# BL808 register map
Vendor: Bouffalo Lab; File version: 0.1
Registers are 32-bit, read-write, reset 0x0 unless marked. A register's access mark holds for its fields unless they carry their own. Offsets are from the block's base; [hi:lo] are bit positions; {n}, {i} and the like mark numbered series.

## FLASH — Quad Serial Flash control
Base 0x2000B000
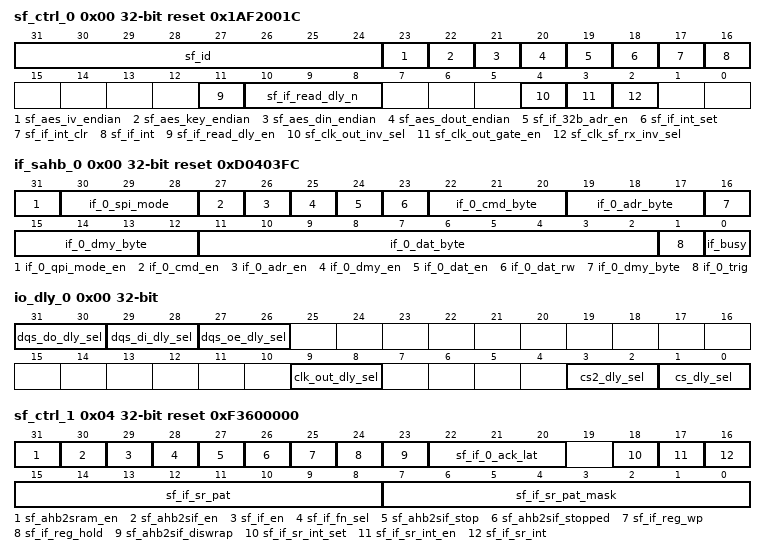
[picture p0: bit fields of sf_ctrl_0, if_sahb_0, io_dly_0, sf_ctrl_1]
0x00 sf_ctrl_0 reset 0x1AF2001C
  [31:24] sf_id, [23] sf_aes_iv_endian, [22] sf_aes_key_endian, [21] sf_aes_din_endian, [20] sf_aes_dout_endian, [19] sf_if_32b_adr_en, [18] sf_if_int_set, [17] sf_if_int_clr, [16] sf_if_int ro, [11] sf_if_read_dly_en, [10:8] sf_if_read_dly_n, [4] sf_clk_out_inv_sel, [3] sf_clk_out_gate_en, [2] sf_clk_sf_rx_inv_sel
0x00 if_sahb_0 reset 0xD0403FC — sf_if_sahb_0
  [31] if_0_qpi_mode_en, [30:28] if_0_spi_mode, [27] if_0_cmd_en, [26] if_0_adr_en, [25] if_0_dmy_en, [24] if_0_dat_en, [23] if_0_dat_rw, [22:20] if_0_cmd_byte, [19:17] if_0_adr_byte, [16:12] if_0_dmy_byte, [11:2] if_0_dat_byte, [1] if_0_trig, [0] if_busy ro
0x00 io_dly_0 — if_io_dly_0
  [31:30] dqs_do_dly_sel, [29:28] dqs_di_dly_sel, [27:26] dqs_oe_dly_sel, [9:8] clk_out_dly_sel, [3:2] cs2_dly_sel, [1:0] cs_dly_sel
{0x0+4i} sf_aes_key_{i} (i=0..7)
0x04 sf_ctrl_1 reset 0xF3600000
  [31] sf_ahb2sram_en, [30] sf_ahb2sif_en, [29] sf_if_en, [28] sf_if_fn_sel, [27] sf_ahb2sif_stop, [26] sf_ahb2sif_stopped ro, [25] sf_if_reg_wp, [24] sf_if_reg_hold, [23] sf_ahb2sif_diswrap, [22:20] sf_if_0_ack_lat, [18] sf_if_sr_int_set, [17] sf_if_sr_int_en, [16] sf_if_sr_int ro, [15:8] sf_if_sr_pat, [7:0] sf_if_sr_pat_mask
0x04 if_sahb_1 reset 0x3000000 — sf_if_sahb_1
  [31:0] if_0_cmd_buf_0
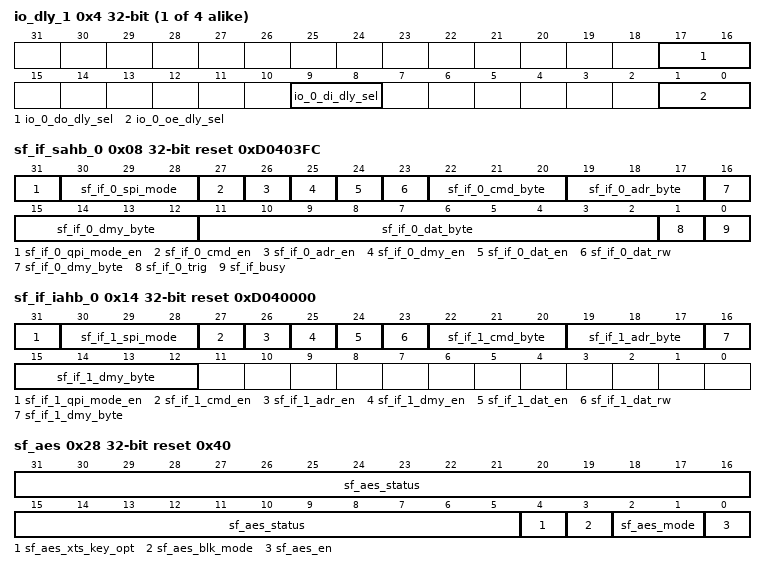
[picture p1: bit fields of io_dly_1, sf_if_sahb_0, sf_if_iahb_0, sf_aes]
{0x0+4i} io_dly_{i} (i=1..4) — if_io_dly_{i}
  [17:16] io_{i-1}_do_dly_sel, [9:8] io_{i-1}_di_dly_sel, [1:0] io_{i-1}_oe_dly_sel
0x08 sf_if_sahb_0 reset 0xD0403FC
  [31] sf_if_0_qpi_mode_en, [30:28] sf_if_0_spi_mode, [27] sf_if_0_cmd_en, [26] sf_if_0_adr_en, [25] sf_if_0_dmy_en, [24] sf_if_0_dat_en, [23] sf_if_0_dat_rw, [22:20] sf_if_0_cmd_byte, [19:17] sf_if_0_adr_byte, [16:12] sf_if_0_dmy_byte, [11:2] sf_if_0_dat_byte, [1] sf_if_0_trig, [0] sf_if_busy ro
0x08 if_sahb_2 — sf_if_sahb_2
  [31:0] if_0_cmd_buf_1
0x0C sf_if_sahb_1 reset 0x3000000
  [31:0] sf_if_0_cmd_buf_0
0x10 sf_if_sahb_2
  [31:0] sf_if_0_cmd_buf_1
0x14 sf_if_iahb_0 reset 0xD040000
  [31] sf_if_1_qpi_mode_en, [30:28] sf_if_1_spi_mode, [27] sf_if_1_cmd_en, [26] sf_if_1_adr_en, [25] sf_if_1_dmy_en, [24] sf_if_1_dat_en, [23] sf_if_1_dat_rw, [22:20] sf_if_1_cmd_byte, [19:17] sf_if_1_adr_byte, [16:12] sf_if_1_dmy_byte
0x18 sf_if_iahb_1 reset 0x3000000
  [31:0] sf_if_1_cmd_buf_0
0x1C sf_if_iahb_2
  [31:0] sf_if_1_cmd_buf_1
0x20 sf_if_status_0
  [31:0] sf_if_status_0 ro
{0x20+4i} sf_aes_iv_w{i} (i=0..3)
0x24 sf_if_status_1 reset 0x20000000
  [31:0] sf_if_status_1 ro
0x28 sf_aes reset 0x40
  [31:5] sf_aes_status ro, [4] sf_aes_xts_key_opt, [3] sf_aes_blk_mode, [2:1] sf_aes_mode, [0] sf_aes_en
0x2C sf_ahb2sif_status reset 0x1010003
  [31:0] sf_ahb2sif_status ro
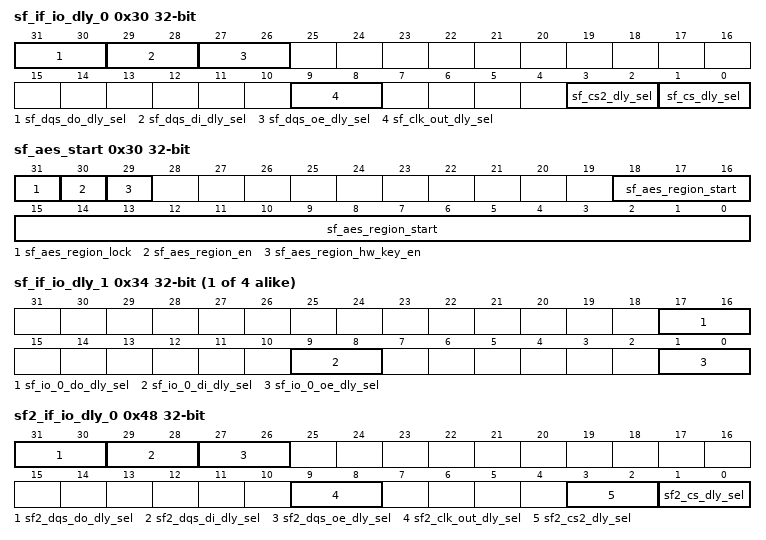
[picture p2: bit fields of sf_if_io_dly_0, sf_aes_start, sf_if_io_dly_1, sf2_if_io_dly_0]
0x30 sf_if_io_dly_0
  [31:30] sf_dqs_do_dly_sel, [29:28] sf_dqs_di_dly_sel, [27:26] sf_dqs_oe_dly_sel, [9:8] sf_clk_out_dly_sel, [3:2] sf_cs2_dly_sel, [1:0] sf_cs_dly_sel
0x30 sf_aes_start
  [31] sf_aes_region_lock, [30] sf_aes_region_en, [29] sf_aes_region_hw_key_en, [18:0] sf_aes_region_start
{0x30+4i} sf_if_io_dly_{i} (i=1..4)
  [17:16] sf_io_{i-1}_do_dly_sel, [9:8] sf_io_{i-1}_di_dly_sel, [1:0] sf_io_{i-1}_oe_dly_sel
0x34 sf_aes_end reset 0x3FFF
  [18:0] sf_aes_region_end
0x44 sf_reserved reset 0xFFFF
0x48 sf2_if_io_dly_0
  [31:30] sf2_dqs_do_dly_sel, [29:28] sf2_dqs_di_dly_sel, [27:26] sf2_dqs_oe_dly_sel, [9:8] sf2_clk_out_dly_sel, [3:2] sf2_cs2_dly_sel, [1:0] sf2_cs_dly_sel
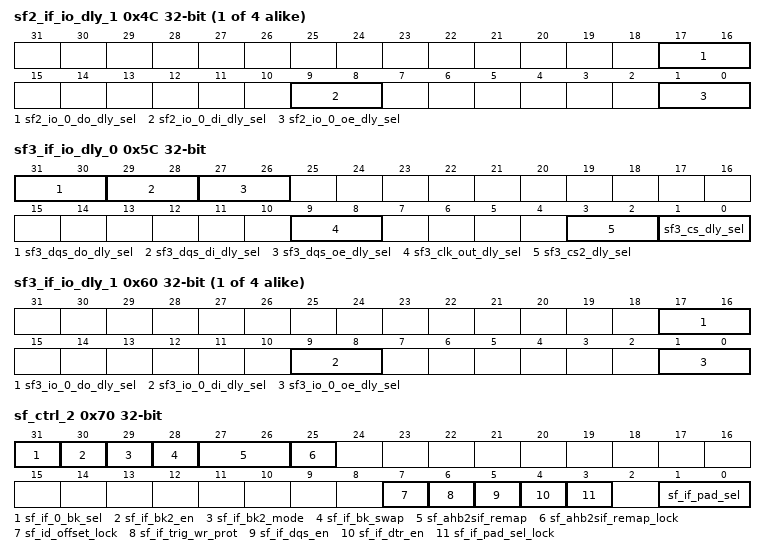
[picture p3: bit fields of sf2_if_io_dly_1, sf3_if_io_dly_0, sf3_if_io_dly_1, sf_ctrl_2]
{0x48+4i} sf2_if_io_dly_{i} (i=1..4)
  [17:16] sf2_io_{i-1}_do_dly_sel, [9:8] sf2_io_{i-1}_di_dly_sel, [1:0] sf2_io_{i-1}_oe_dly_sel
0x5C sf3_if_io_dly_0
  [31:30] sf3_dqs_do_dly_sel, [29:28] sf3_dqs_di_dly_sel, [27:26] sf3_dqs_oe_dly_sel, [9:8] sf3_clk_out_dly_sel, [3:2] sf3_cs2_dly_sel, [1:0] sf3_cs_dly_sel
{0x5C+4i} sf3_if_io_dly_{i} (i=1..4)
  [17:16] sf3_io_{i-1}_do_dly_sel, [9:8] sf3_io_{i-1}_di_dly_sel, [1:0] sf3_io_{i-1}_oe_dly_sel
0x70 sf_ctrl_2
  [31] sf_if_0_bk_sel, [30] sf_if_bk2_en, [29] sf_if_bk2_mode, [28] sf_if_bk_swap, [27:26] sf_ahb2sif_remap, [25] sf_ahb2sif_remap_lock, [7] sf_id_offset_lock, [6] sf_if_trig_wr_prot, [5] sf_if_dqs_en, [4] sf_if_dtr_en, [3] sf_if_pad_sel_lock, [1:0] sf_if_pad_sel
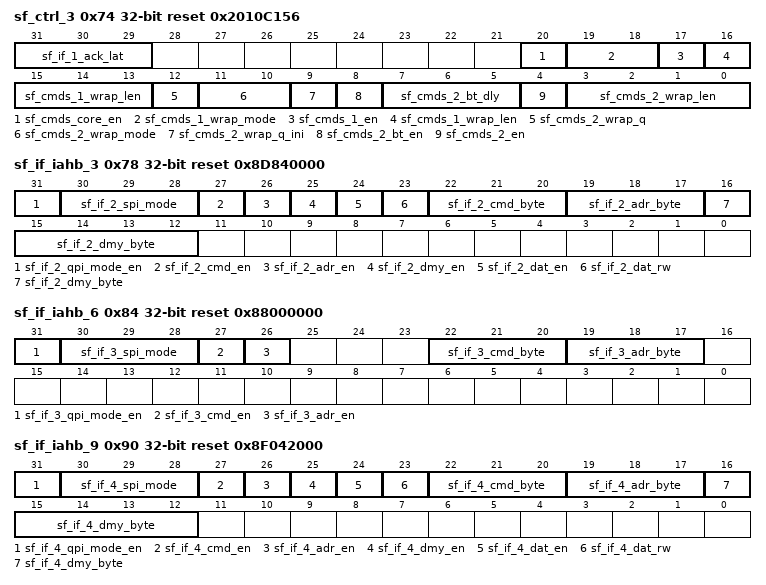
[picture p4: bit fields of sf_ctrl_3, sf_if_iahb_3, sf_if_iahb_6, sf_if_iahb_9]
0x74 sf_ctrl_3 reset 0x2010C156
  [31:29] sf_if_1_ack_lat, [20] sf_cmds_core_en, [19:18] sf_cmds_1_wrap_mode, [17] sf_cmds_1_en, [16:13] sf_cmds_1_wrap_len, [12] sf_cmds_2_wrap_q ro, [11:10] sf_cmds_2_wrap_mode, [9] sf_cmds_2_wrap_q_ini, [8] sf_cmds_2_bt_en, [7:5] sf_cmds_2_bt_dly, [4] sf_cmds_2_en, [3:0] sf_cmds_2_wrap_len
0x78 sf_if_iahb_3 reset 0x8D840000
  [31] sf_if_2_qpi_mode_en, [30:28] sf_if_2_spi_mode, [27] sf_if_2_cmd_en, [26] sf_if_2_adr_en, [25] sf_if_2_dmy_en, [24] sf_if_2_dat_en, [23] sf_if_2_dat_rw, [22:20] sf_if_2_cmd_byte, [19:17] sf_if_2_adr_byte, [16:12] sf_if_2_dmy_byte
0x7C sf_if_iahb_4 reset 0x38000000
  [31:0] sf_if_2_cmd_buf_0
0x80 sf_if_iahb_5
  [31:0] sf_if_2_cmd_buf_1
0x84 sf_if_iahb_6 reset 0x88000000
  [31] sf_if_3_qpi_mode_en, [30:28] sf_if_3_spi_mode, [27] sf_if_3_cmd_en, [26] sf_if_3_adr_en, [22:20] sf_if_3_cmd_byte, [19:17] sf_if_3_adr_byte
0x88 sf_if_iahb_7
0x8C sf_if_iahb_8
  [31:0] sf_if_3_cmd_buf_1
0x90 sf_if_iahb_9 reset 0x8F042000
  [31] sf_if_4_qpi_mode_en, [30:28] sf_if_4_spi_mode, [27] sf_if_4_cmd_en, [26] sf_if_4_adr_en, [25] sf_if_4_dmy_en, [24] sf_if_4_dat_en, [23] sf_if_4_dat_rw, [22:20] sf_if_4_cmd_byte, [19:17] sf_if_4_adr_byte, [16:12] sf_if_4_dmy_byte
0x94 sf_if_iahb_10
0x98 sf_if_iahb_11
  [31:0] sf_if_4_cmd_buf_1
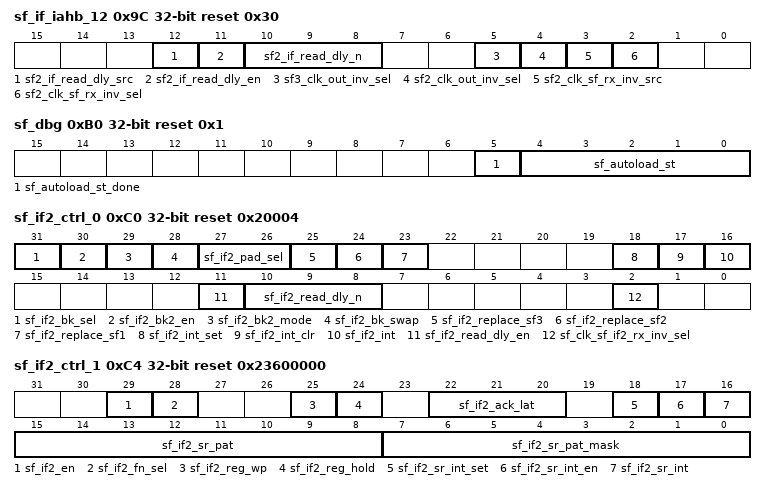
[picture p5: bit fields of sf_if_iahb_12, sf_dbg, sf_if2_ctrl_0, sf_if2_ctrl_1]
0x9C sf_if_iahb_12 reset 0x30
  [12] sf2_if_read_dly_src, [11] sf2_if_read_dly_en, [10:8] sf2_if_read_dly_n, [5] sf3_clk_out_inv_sel, [4] sf2_clk_out_inv_sel, [3] sf2_clk_sf_rx_inv_src, [2] sf2_clk_sf_rx_inv_sel
0xA0 sf_id0_offset
  [27:0] sf_id0_offset
0xA4 sf_id1_offset
  [27:0] sf_id1_offset
0xA8 sf_bk2_id0_offset
  [27:0] sf_bk2_id0_offset
0xAC sf_bk2_id1_offset
  [27:0] sf_bk2_id1_offset
0xB0 sf_dbg reset 0x1
  [5] sf_autoload_st_done ro, [4:0] sf_autoload_st ro
0xC0 sf_if2_ctrl_0 reset 0x20004
  [31] sf_if2_bk_sel, [30] sf_if2_bk2_en, [29] sf_if2_bk2_mode, [28] sf_if2_bk_swap, [27:26] sf_if2_pad_sel, [25] sf_if2_replace_sf3, [24] sf_if2_replace_sf2, [23] sf_if2_replace_sf1, [18] sf_if2_int_set, [17] sf_if2_int_clr, [16] sf_if2_int ro, [11] sf_if2_read_dly_en, [10:8] sf_if2_read_dly_n, [2] sf_clk_sf_if2_rx_inv_sel
0xC4 sf_if2_ctrl_1 reset 0x23600000
  [29] sf_if2_en, [28] sf_if2_fn_sel, [25] sf_if2_reg_wp, [24] sf_if2_reg_hold, [22:20] sf_if2_ack_lat, [18] sf_if2_sr_int_set, [17] sf_if2_sr_int_en, [16] sf_if2_sr_int ro, [15:8] sf_if2_sr_pat, [7:0] sf_if2_sr_pat_mask
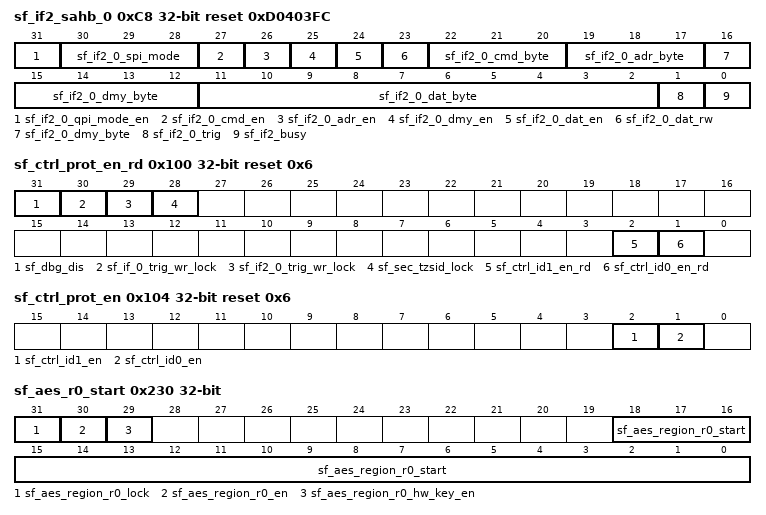
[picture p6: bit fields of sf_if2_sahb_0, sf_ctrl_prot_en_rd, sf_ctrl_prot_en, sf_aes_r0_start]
0xC8 sf_if2_sahb_0 reset 0xD0403FC
  [31] sf_if2_0_qpi_mode_en, [30:28] sf_if2_0_spi_mode, [27] sf_if2_0_cmd_en, [26] sf_if2_0_adr_en, [25] sf_if2_0_dmy_en, [24] sf_if2_0_dat_en, [23] sf_if2_0_dat_rw, [22:20] sf_if2_0_cmd_byte, [19:17] sf_if2_0_adr_byte, [16:12] sf_if2_0_dmy_byte, [11:2] sf_if2_0_dat_byte, [1] sf_if2_0_trig, [0] sf_if2_busy ro
0xCC sf_if2_sahb_1 reset 0x3000000
  [31:0] sf_if2_0_cmd_buf_0
0xD0 sf_if2_sahb_2
  [31:0] sf_if2_0_cmd_buf_1
0x100 sf_ctrl_prot_en_rd reset 0x6
  [31] sf_dbg_dis ro, [30] sf_if_0_trig_wr_lock ro, [29] sf_if2_0_trig_wr_lock ro, [28] sf_sec_tzsid_lock ro, [2] sf_ctrl_id1_en_rd ro, [1] sf_ctrl_id0_en_rd ro
0x104 sf_ctrl_prot_en reset 0x6
  [2] sf_ctrl_id1_en, [1] sf_ctrl_id0_en
{0x200+4i} sf_aes_key_r0_{i} (i=0..7)
{0x220+4i} sf_aes_iv_r0_w{i} (i=0..3)
0x230 sf_aes_r0_start
  [31] sf_aes_region_r0_lock, [30] sf_aes_region_r0_en, [29] sf_aes_region_r0_hw_key_en, [18:0] sf_aes_region_r0_start
0x234 sf_aes_r0_end reset 0x3FFF
  [18:0] sf_aes_region_r0_end
{0x280+4i} sf_aes_key_r1_{i} (i=0..7)
{0x2A0+4i} sf_aes_iv_r1_w{i} (i=0..3)
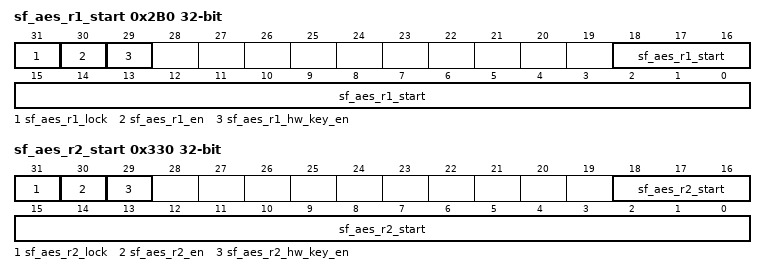
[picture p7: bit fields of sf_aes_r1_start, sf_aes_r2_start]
0x2B0 sf_aes_r1_start
  [31] sf_aes_r1_lock, [30] sf_aes_r1_en, [29] sf_aes_r1_hw_key_en, [18:0] sf_aes_r1_start
0x2B4 sf_aes_r1_end reset 0x3FFF
  [18:0] sf_aes_r1_end
{0x300+4i} sf_aes_key_r2_{i} (i=0..7)
{0x320+4i} sf_aes_iv_r2_w{i} (i=0..3)
0x330 sf_aes_r2_start
  [31] sf_aes_r2_lock, [30] sf_aes_r2_en, [29] sf_aes_r2_hw_key_en, [18:0] sf_aes_r2_start
0x334 sf_aes_r2_end reset 0x3FFF
  [18:0] sf_aes_r2_end
